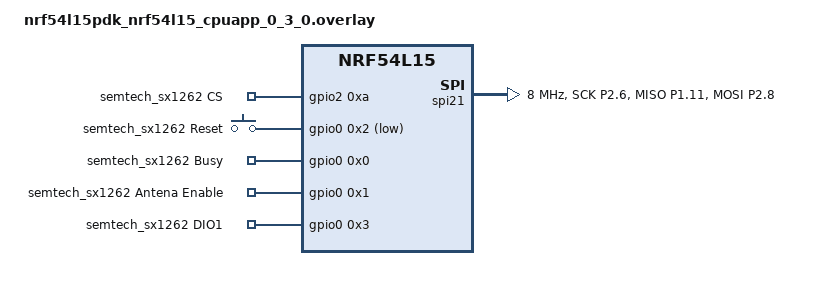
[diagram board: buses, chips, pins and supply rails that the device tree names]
/*
 * Copyright (c) 2024 Nordic Semiconductor ASA
 *
 * SPDX-License-Identifier: LicenseRef-Nordic-5-Clause
 */


 &pinctrl {
	spi21_default: spi21_default {
		group1 {
			psels = <NRF_PSEL(SPIM_SCK, 2, 6)>,
				<NRF_PSEL(SPIM_MISO, 1, 11)>,
				<NRF_PSEL(SPIM_MOSI, 2, 8)>;
		};
	};

	spi21_sleep: spi21_sleep {
		group1 {
			psels = <NRF_PSEL(SPIM_SCK, 2, 6)>,
				<NRF_PSEL(SPIM_MISO, 1, 11)>,
				<NRF_PSEL(SPIM_MOSI, 2, 8)>;
			low-power-enable;
		};
	};
};

 sid_semtech: &spi21 {
	compatible = "nordic,nrf-spim";
	status = "okay";
	pinctrl-0 = <&spi21_default>;
	pinctrl-1 = <&spi21_sleep>;
	pinctrl-names = "default", "sleep";
	clock-frequency = <DT_FREQ_M(8)>;
};

/{
	semtech_sx1262_gpios{
		compatible = "gpio-keys";
		semtech_sx1262_cs: cs {
			gpios = <&gpio2 0xa GPIO_PULL_UP>;
			label = "semtech_sx1262 CS";
		};
		semtech_sx1262_reset_gpios: reset {
			gpios = <&gpio0 0x2 (GPIO_ACTIVE_LOW|GPIO_PULL_UP)>;
			label = "semtech_sx1262 Reset";
		};
		semtech_sx1262_busy_gpios: busy {
			gpios = <&gpio0 0x0 0x0>;
			label = "semtech_sx1262 Busy";
		};
		semtech_sx1262_antenna_enable_gpios: antena_enable {
			gpios = <&gpio0 0x1 0x0>;
			label = "semtech_sx1262 Antena Enable";
		};
		semtech_sx1262_dio1_gpios: dio1 {
			gpios = <&gpio0 0x3  0x0>;
			label = "semtech_sx1262 DIO1";
		};
	};	
};

&gpio1 {
	status = "okay";
};

&gpio2 {
	status = "okay";
};

&gpio0 {
	status = "okay";
};
